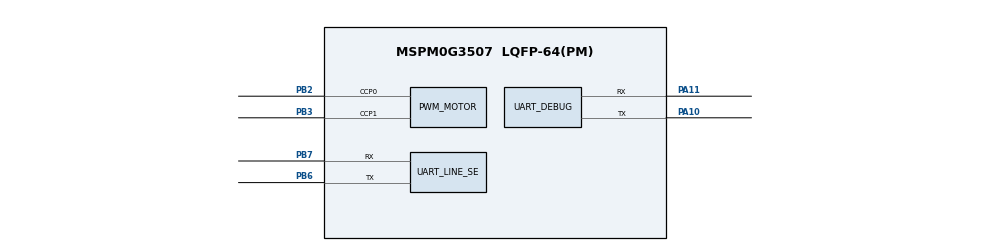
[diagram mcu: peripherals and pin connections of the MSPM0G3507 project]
/**
 * H2026 Q2 MSPM0G3507 peripheral ownership.
 *
 * This is a new hardware configuration for the frozen C07A/S27F-S28A
 * vehicle.  It is intentionally unrelated to the old generic-car SysConfig.
 */
//@cliArgs --device "MSPM0G350X" --package "LQFP-64(PM)" --part "Default"
//@v2CliArgs --device "MSPM0G3507" --package "LQFP-64(PM)"
// @cliArgs --board /ti/boards/LP_MSPM0G3507 --rtos nortos

const GPIO   = scripting.addModule("/ti/driverlib/GPIO", {}, false);
const PWM    = scripting.addModule("/ti/driverlib/PWM", {}, false);
const TIMER  = scripting.addModule("/ti/driverlib/TIMER", {}, false);
const UART   = scripting.addModule("/ti/driverlib/UART", {}, false);
const SYSCTL = scripting.addModule("/ti/driverlib/SYSCTL");

const PWM_MOTOR = PWM.addInstance();
const TIMER_CONTROL = TIMER.addInstance();
const UART_DEBUG = UART.addInstance();
const UART_LINE_SENSOR = UART.addInstance();

const GPIO_ENCODER_LEFT  = GPIO.addInstance();
const GPIO_ENCODER_RIGHT = GPIO.addInstance();
const GPIO_MOTOR_DIR     = GPIO.addInstance();
const GPIO_UI            = GPIO.addInstance();
const GPIO_OLED          = GPIO.addInstance();
const GPIO_LINE_SOFT_I2C = GPIO.addInstance();

const Board = scripting.addModule("/ti/driverlib/Board", {}, false);

SYSCTL.forceDefaultClkConfig = true;
SYSCTL.clockTreeEn = true;

/* Integrated D103A/TB6612: PWMA/PWMB plus two GPIO direction pairs. */
PWM_MOTOR.$name = "PWM_MOTOR";
PWM_MOTOR.clockPrescale = 1;
PWM_MOTOR.timerCount = 8000;
PWM_MOTOR.timerStartTimer = false;
PWM_MOTOR.peripheral.$assign = "TIMA1";
PWM_MOTOR.peripheral.ccp0Pin.$assign = "PB2";
PWM_MOTOR.peripheral.ccp1Pin.$assign = "PB3";
PWM_MOTOR.PWM_CHANNEL_0.$name = "TB_A_PWM";
PWM_MOTOR.PWM_CHANNEL_0.dutyCycle = 0;
PWM_MOTOR.PWM_CHANNEL_1.$name = "TB_B_PWM";
PWM_MOTOR.PWM_CHANNEL_1.dutyCycle = 0;

/* Hard 5 ms scheduler source.  ISR only records pending/overrun counters. */
TIMER_CONTROL.$name = "TIMER_CONTROL";
TIMER_CONTROL.profile = "Basic_Periodic";
TIMER_CONTROL.timerPeriod = "5 ms";
TIMER_CONTROL.timerStartTimer = false;
TIMER_CONTROL.peripheral.$assign = "TIMG7";

/*
 * Legacy U3 PB16/PB17 software-I2C pins remain configured as released inputs
 * while the harness is moved to the sensor's native UART.  They are not read
 * by the control loop and must be physically disconnected from HiWonder.
 */
GPIO_LINE_SOFT_I2C.$name = "GPIO_LINE_SOFT_I2C";
GPIO_LINE_SOFT_I2C.port = "PORTB";
GPIO_LINE_SOFT_I2C.associatedPins.create(2);
GPIO_LINE_SOFT_I2C.associatedPins[0].$name = "LINE_SCL";
GPIO_LINE_SOFT_I2C.associatedPins[0].assignedPin = "16";
GPIO_LINE_SOFT_I2C.associatedPins[0].direction = "INPUT";
GPIO_LINE_SOFT_I2C.associatedPins[1].$name = "LINE_SDA";
GPIO_LINE_SOFT_I2C.associatedPins[1].assignedPin = "17";
GPIO_LINE_SOFT_I2C.associatedPins[1].direction = "INPUT";

UART_DEBUG.$name = "UART_DEBUG";
UART_DEBUG.enableFIFO = true;
UART_DEBUG.enableDMARX = false;
UART_DEBUG.enableDMATX = false;
UART_DEBUG.targetBaudRate = 115200;
/* Dedicated debug serial path; it does not share the line-sensor bus. */
UART_DEBUG.peripheral.$assign = "UART0";
UART_DEBUG.peripheral.txPin.$assign = "PA10";
UART_DEBUG.peripheral.rxPin.$assign = "PA11";

/*
 * HiWonder LineFollower_8CH v1.0 native UART, 115200 8N1.
 * H8-2 PB6 (MCU TX) -> sensor RX; H8-3 PB7 (MCU RX) <- sensor TX.
 * The removable Bluetooth module and K230 must both remain disconnected.
 */
UART_LINE_SENSOR.$name = "UART_LINE_SENSOR";
UART_LINE_SENSOR.enableFIFO = true;
UART_LINE_SENSOR.enableDMARX = false;
UART_LINE_SENSOR.enableDMATX = false;
UART_LINE_SENSOR.targetBaudRate = 115200;
UART_LINE_SENSOR.peripheral.$assign = "UART1";
UART_LINE_SENSOR.peripheral.txPin.$assign = "PB6";
UART_LINE_SENSOR.peripheral.rxPin.$assign = "PB7";

/* Both encoder phases use GPIO rise/fall interrupts (four-edge decoding). */
GPIO_ENCODER_LEFT.$name = "GPIO_ENCODER_LEFT";
GPIO_ENCODER_LEFT.port = "PORTA";
GPIO_ENCODER_LEFT.associatedPins.create(2);
GPIO_ENCODER_LEFT.associatedPins[0].$name = "LEFT_A";
GPIO_ENCODER_LEFT.associatedPins[0].assignedPin = "25";
GPIO_ENCODER_LEFT.associatedPins[0].direction = "INPUT";
GPIO_ENCODER_LEFT.associatedPins[0].interruptEn = true;
GPIO_ENCODER_LEFT.associatedPins[0].polarity = "RISE_FALL";
GPIO_ENCODER_LEFT.associatedPins[1].$name = "LEFT_B";
GPIO_ENCODER_LEFT.associatedPins[1].assignedPin = "26";
GPIO_ENCODER_LEFT.associatedPins[1].direction = "INPUT";
GPIO_ENCODER_LEFT.associatedPins[1].interruptEn = true;
GPIO_ENCODER_LEFT.associatedPins[1].polarity = "RISE_FALL";

GPIO_ENCODER_RIGHT.$name = "GPIO_ENCODER_RIGHT";
GPIO_ENCODER_RIGHT.port = "PORTB";
GPIO_ENCODER_RIGHT.associatedPins.create(2);
GPIO_ENCODER_RIGHT.associatedPins[0].$name = "RIGHT_A";
GPIO_ENCODER_RIGHT.associatedPins[0].assignedPin = "20";
GPIO_ENCODER_RIGHT.associatedPins[0].direction = "INPUT";
GPIO_ENCODER_RIGHT.associatedPins[0].interruptEn = true;
GPIO_ENCODER_RIGHT.associatedPins[0].polarity = "RISE_FALL";
GPIO_ENCODER_RIGHT.associatedPins[1].$name = "RIGHT_B";
GPIO_ENCODER_RIGHT.associatedPins[1].assignedPin = "24";
GPIO_ENCODER_RIGHT.associatedPins[1].direction = "INPUT";
GPIO_ENCODER_RIGHT.associatedPins[1].interruptEn = true;
GPIO_ENCODER_RIGHT.associatedPins[1].polarity = "RISE_FALL";

/* D103A/TB6612 direction pins.  All four start low, which coasts both motors. */
GPIO_MOTOR_DIR.$name = "GPIO_MOTOR_DIR";
GPIO_MOTOR_DIR.associatedPins.create(4);
GPIO_MOTOR_DIR.associatedPins[0].$name = "TB_A_IN1";
GPIO_MOTOR_DIR.associatedPins[0].assignedPort = "PORTA";
GPIO_MOTOR_DIR.associatedPins[0].assignedPin = "14";
GPIO_MOTOR_DIR.associatedPins[0].initialValue = "CLEARED";
GPIO_MOTOR_DIR.associatedPins[1].$name = "TB_A_IN2";
GPIO_MOTOR_DIR.associatedPins[1].assignedPort = "PORTA";
GPIO_MOTOR_DIR.associatedPins[1].assignedPin = "13";
GPIO_MOTOR_DIR.associatedPins[1].initialValue = "CLEARED";
GPIO_MOTOR_DIR.associatedPins[2].$name = "TB_B_IN1";
GPIO_MOTOR_DIR.associatedPins[2].assignedPort = "PORTA";
GPIO_MOTOR_DIR.associatedPins[2].assignedPin = "16";
GPIO_MOTOR_DIR.associatedPins[2].initialValue = "CLEARED";
GPIO_MOTOR_DIR.associatedPins[3].$name = "TB_B_IN2";
GPIO_MOTOR_DIR.associatedPins[3].assignedPort = "PORTA";
GPIO_MOTOR_DIR.associatedPins[3].assignedPin = "17";
GPIO_MOTOR_DIR.associatedPins[3].initialValue = "CLEARED";

GPIO_UI.$name = "GPIO_UI";
GPIO_UI.associatedPins.create(2);
GPIO_UI.associatedPins[0].$name = "START";
GPIO_UI.associatedPins[0].assignedPort = "PORTA";
GPIO_UI.associatedPins[0].assignedPin = "18";
GPIO_UI.associatedPins[0].direction = "INPUT";
GPIO_UI.associatedPins[0].internalResistor = "PULL_UP";
GPIO_UI.associatedPins[1].$name = "STATUS_LED";
GPIO_UI.associatedPins[1].assignedPort = "PORTB";
GPIO_UI.associatedPins[1].assignedPin = "9";
GPIO_UI.associatedPins[1].initialValue = "CLEARED";

/* Installed four-wire OLED: SCL/SDA/RST/DC, bit-banged at low refresh rate. */
GPIO_OLED.$name = "GPIO_OLED";
GPIO_OLED.associatedPins.create(4);
GPIO_OLED.associatedPins[0].$name = "SCL";
GPIO_OLED.associatedPins[0].assignedPort = "PORTA";
GPIO_OLED.associatedPins[0].assignedPin = "28";
GPIO_OLED.associatedPins[0].initialValue = "CLEARED";
GPIO_OLED.associatedPins[1].$name = "SDA";
GPIO_OLED.associatedPins[1].assignedPort = "PORTA";
GPIO_OLED.associatedPins[1].assignedPin = "31";
GPIO_OLED.associatedPins[1].initialValue = "CLEARED";
GPIO_OLED.associatedPins[2].$name = "RST";
GPIO_OLED.associatedPins[2].assignedPort = "PORTB";
GPIO_OLED.associatedPins[2].assignedPin = "14";
GPIO_OLED.associatedPins[2].initialValue = "SET";
GPIO_OLED.associatedPins[3].$name = "DC";
GPIO_OLED.associatedPins[3].assignedPort = "PORTB";
GPIO_OLED.associatedPins[3].assignedPin = "15";
GPIO_OLED.associatedPins[3].initialValue = "CLEARED";
